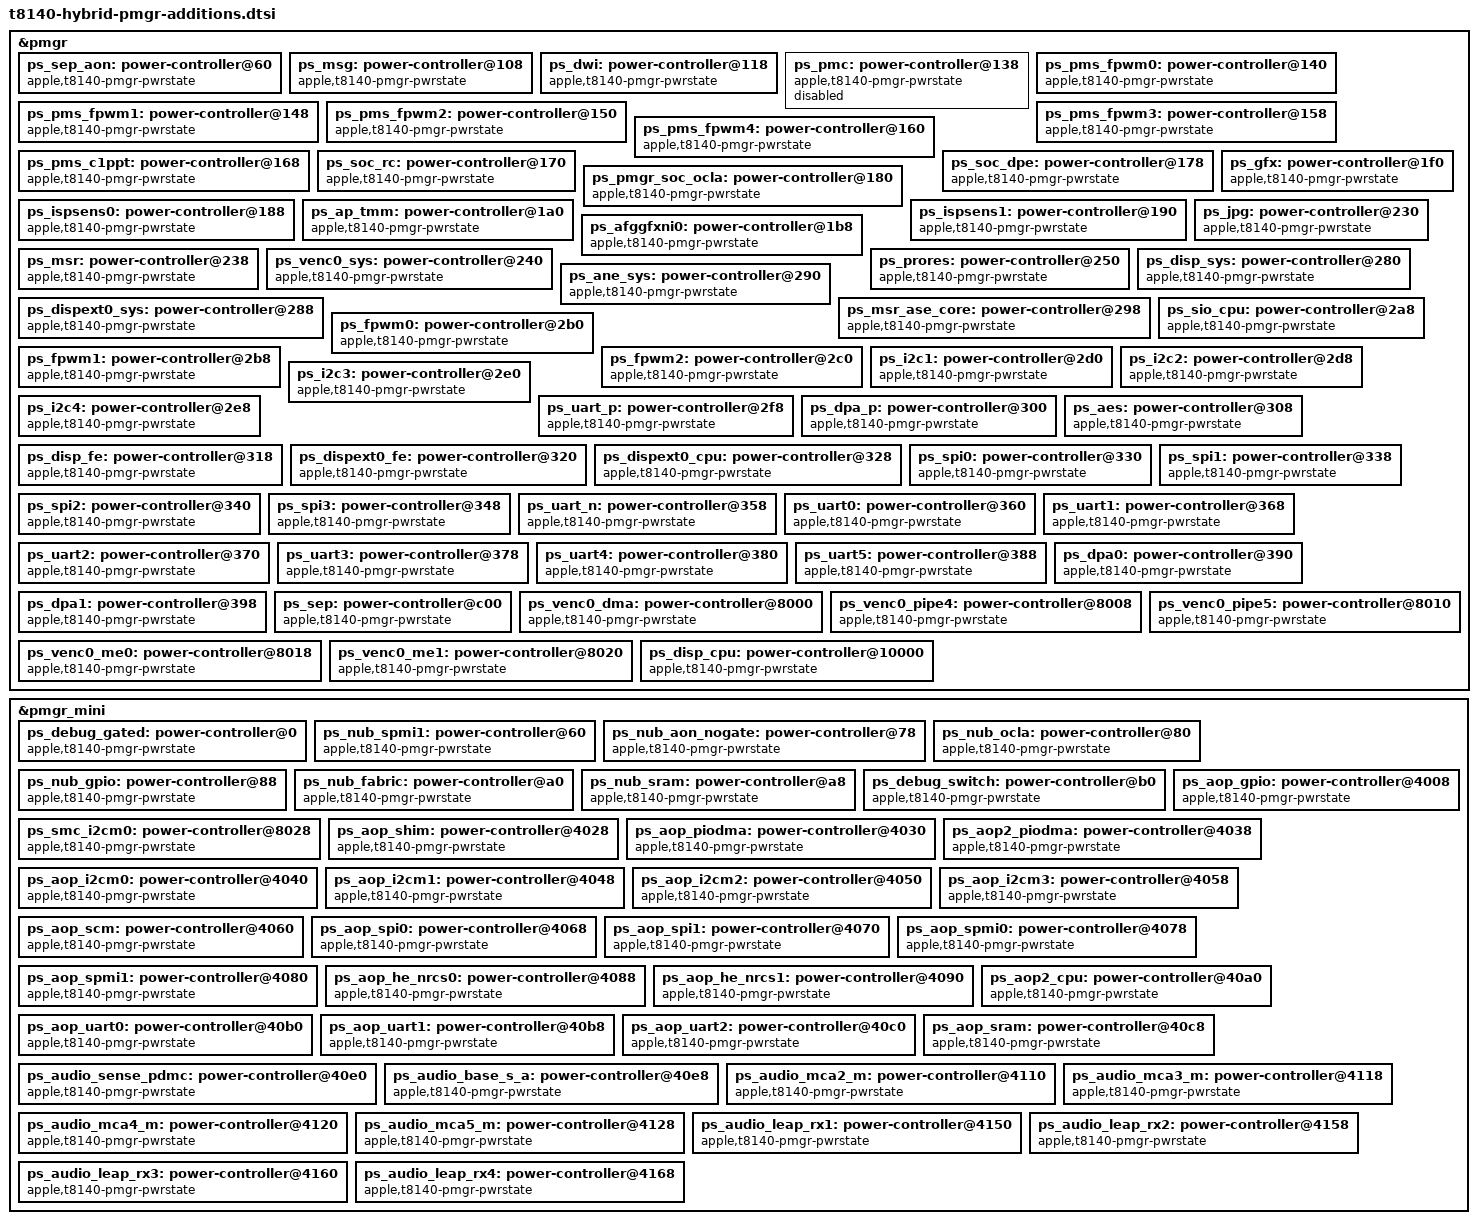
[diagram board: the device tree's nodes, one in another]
// SPDX-License-Identifier: GPL-2.0+ OR MIT
/* Accepted full-platform companion nodes from Linux 2954e3f8; clean t8140-pmgr.dtsi remains authoritative for shared CPU, ANS, PMP and AV nodes. */

&pmgr {
	ps_sep_aon: power-controller@60 {
			compatible = "apple,t8140-pmgr-pwrstate", "apple,t8103-pmgr-pwrstate";
			reg = <0x60 4>;
			#power-domain-cells = <0>;
			#reset-cells = <0>;
			label = "sep_aon";
			apple,always-on;
		};
};

&pmgr {
	ps_msg: power-controller@108 {
			compatible = "apple,t8140-pmgr-pwrstate", "apple,t8103-pmgr-pwrstate";
			reg = <0x108 4>;
			#power-domain-cells = <0>;
			#reset-cells = <0>;
			label = "msg";
		};
};

&pmgr {
	ps_dwi: power-controller@118 {
			compatible = "apple,t8140-pmgr-pwrstate", "apple,t8103-pmgr-pwrstate";
			reg = <0x118 4>;
			#power-domain-cells = <0>;
			#reset-cells = <0>;
			label = "dwi";
		};
};

&pmgr {
	ps_pmc: power-controller@138 {
			compatible = "apple,t8140-pmgr-pwrstate", "apple,t8103-pmgr-pwrstate";
			reg = <0x138 4>;
			#power-domain-cells = <0>;
			#reset-cells = <0>;
			label = "pmc";
			/* Preserve iBoot's PMC state while the PMP firmware boots. */
			status = "disabled";
		};
};

&pmgr {
	ps_pms_fpwm0: power-controller@140 {
			compatible = "apple,t8140-pmgr-pwrstate", "apple,t8103-pmgr-pwrstate";
			reg = <0x140 4>;
			#power-domain-cells = <0>;
			#reset-cells = <0>;
			label = "pms_fpwm0";
		};
};

&pmgr {
	ps_pms_fpwm1: power-controller@148 {
			compatible = "apple,t8140-pmgr-pwrstate", "apple,t8103-pmgr-pwrstate";
			reg = <0x148 4>;
			#power-domain-cells = <0>;
			#reset-cells = <0>;
			label = "pms_fpwm1";
		};
};

&pmgr {
	ps_pms_fpwm2: power-controller@150 {
			compatible = "apple,t8140-pmgr-pwrstate", "apple,t8103-pmgr-pwrstate";
			reg = <0x150 4>;
			#power-domain-cells = <0>;
			#reset-cells = <0>;
			label = "pms_fpwm2";
		};
};

&pmgr {
	ps_pms_fpwm3: power-controller@158 {
			compatible = "apple,t8140-pmgr-pwrstate", "apple,t8103-pmgr-pwrstate";
			reg = <0x158 4>;
			#power-domain-cells = <0>;
			#reset-cells = <0>;
			label = "pms_fpwm3";
		};
};

&pmgr {
	ps_pms_fpwm4: power-controller@160 {
			compatible = "apple,t8140-pmgr-pwrstate", "apple,t8103-pmgr-pwrstate";
			reg = <0x160 4>;
			#power-domain-cells = <0>;
			#reset-cells = <0>;
			label = "pms_fpwm4";
		};
};

&pmgr {
	ps_pms_c1ppt: power-controller@168 {
			compatible = "apple,t8140-pmgr-pwrstate", "apple,t8103-pmgr-pwrstate";
			reg = <0x168 4>;
			#power-domain-cells = <0>;
			#reset-cells = <0>;
			label = "pms_c1ppt";
			apple,always-on;
		};
};

&pmgr {
	ps_soc_rc: power-controller@170 {
			compatible = "apple,t8140-pmgr-pwrstate", "apple,t8103-pmgr-pwrstate";
			reg = <0x170 4>;
			#power-domain-cells = <0>;
			#reset-cells = <0>;
			label = "soc_rc";
		};
};

&pmgr {
	ps_soc_dpe: power-controller@178 {
			compatible = "apple,t8140-pmgr-pwrstate", "apple,t8103-pmgr-pwrstate";
			reg = <0x178 4>;
			#power-domain-cells = <0>;
			#reset-cells = <0>;
			label = "soc_dpe";
			apple,always-on;
		};
};

&pmgr {
	ps_pmgr_soc_ocla: power-controller@180 {
			compatible = "apple,t8140-pmgr-pwrstate", "apple,t8103-pmgr-pwrstate";
			reg = <0x180 4>;
			#power-domain-cells = <0>;
			#reset-cells = <0>;
			label = "pmgr_soc_ocla";
		};
};

&pmgr {
	ps_ispsens0: power-controller@188 {
			compatible = "apple,t8140-pmgr-pwrstate", "apple,t8103-pmgr-pwrstate";
			reg = <0x188 4>;
			#power-domain-cells = <0>;
			#reset-cells = <0>;
			label = "ispsens0";
		};
};

&pmgr {
	ps_ispsens1: power-controller@190 {
			compatible = "apple,t8140-pmgr-pwrstate", "apple,t8103-pmgr-pwrstate";
			reg = <0x190 4>;
			#power-domain-cells = <0>;
			#reset-cells = <0>;
			label = "ispsens1";
		};
};

&pmgr {
	ps_ap_tmm: power-controller@1a0 {
			compatible = "apple,t8140-pmgr-pwrstate", "apple,t8103-pmgr-pwrstate";
			reg = <0x1a0 4>;
			#power-domain-cells = <0>;
			#reset-cells = <0>;
			label = "ap_tmm";
		};
};

&pmgr {
	ps_afggfxni0: power-controller@1b8 {
			compatible = "apple,t8140-pmgr-pwrstate", "apple,t8103-pmgr-pwrstate";
			reg = <0x1b8 4>;
			#power-domain-cells = <0>;
			#reset-cells = <0>;
			label = "afggfxni0";
			apple,always-on;
		};
};

&pmgr {
	ps_gfx: power-controller@1f0 {
			compatible = "apple,t8140-pmgr-pwrstate", "apple,t8103-pmgr-pwrstate";
			reg = <0x1f0 4>;
			#power-domain-cells = <0>;
			#reset-cells = <0>;
			label = "gfx";
		};
};

&pmgr {
	ps_jpg: power-controller@230 {
			compatible = "apple,t8140-pmgr-pwrstate", "apple,t8103-pmgr-pwrstate";
			reg = <0x230 4>;
			#power-domain-cells = <0>;
			#reset-cells = <0>;
			label = "jpg";
		};
};

&pmgr {
	ps_msr: power-controller@238 {
			compatible = "apple,t8140-pmgr-pwrstate", "apple,t8103-pmgr-pwrstate";
			reg = <0x238 4>;
			#power-domain-cells = <0>;
			#reset-cells = <0>;
			label = "msr";
		};
};

&pmgr {
	ps_venc0_sys: power-controller@240 {
			compatible = "apple,t8140-pmgr-pwrstate", "apple,t8103-pmgr-pwrstate";
			reg = <0x240 4>;
			#power-domain-cells = <0>;
			#reset-cells = <0>;
			label = "venc0_sys";
		};
};

&pmgr {
	ps_prores: power-controller@250 {
			compatible = "apple,t8140-pmgr-pwrstate", "apple,t8103-pmgr-pwrstate";
			reg = <0x250 4>;
			#power-domain-cells = <0>;
			#reset-cells = <0>;
			label = "prores";
		};
};

&pmgr {
	ps_disp_sys: power-controller@280 {
			compatible = "apple,t8140-pmgr-pwrstate", "apple,t8103-pmgr-pwrstate";
			reg = <0x280 4>;
			#power-domain-cells = <0>;
			#reset-cells = <0>;
			label = "disp_sys";
			apple,always-on; /* TODO: figure out if we can enable PM here */
		};
};

&pmgr {
	ps_dispext0_sys: power-controller@288 {
			compatible = "apple,t8140-pmgr-pwrstate", "apple,t8103-pmgr-pwrstate";
			reg = <0x288 4>;
			#power-domain-cells = <0>;
			#reset-cells = <0>;
			label = "dispext0_sys";
		};
};

&pmgr {
	ps_ane_sys: power-controller@290 {
			compatible = "apple,t8140-pmgr-pwrstate", "apple,t8103-pmgr-pwrstate";
			reg = <0x290 4>;
			#power-domain-cells = <0>;
			#reset-cells = <0>;
			label = "ane_sys";
		};
};

&pmgr {
	ps_msr_ase_core: power-controller@298 {
			compatible = "apple,t8140-pmgr-pwrstate", "apple,t8103-pmgr-pwrstate";
			reg = <0x298 4>;
			#power-domain-cells = <0>;
			#reset-cells = <0>;
			label = "msr_ase_core";
			power-domains = <&ps_msr>;
		};
};

&pmgr {
	ps_sio_cpu: power-controller@2a8 {
			compatible = "apple,t8140-pmgr-pwrstate", "apple,t8103-pmgr-pwrstate";
			reg = <0x2a8 4>;
			#power-domain-cells = <0>;
			#reset-cells = <0>;
			label = "sio_cpu";
		};
};

&pmgr {
	ps_fpwm0: power-controller@2b0 {
			compatible = "apple,t8140-pmgr-pwrstate", "apple,t8103-pmgr-pwrstate";
			reg = <0x2b0 4>;
			#power-domain-cells = <0>;
			#reset-cells = <0>;
			label = "fpwm0";
		};
};

&pmgr {
	ps_fpwm1: power-controller@2b8 {
			compatible = "apple,t8140-pmgr-pwrstate", "apple,t8103-pmgr-pwrstate";
			reg = <0x2b8 4>;
			#power-domain-cells = <0>;
			#reset-cells = <0>;
			label = "fpwm1";
		};
};

&pmgr {
	ps_fpwm2: power-controller@2c0 {
			compatible = "apple,t8140-pmgr-pwrstate", "apple,t8103-pmgr-pwrstate";
			reg = <0x2c0 4>;
			#power-domain-cells = <0>;
			#reset-cells = <0>;
			label = "fpwm2";
		};
};

&pmgr {
	ps_i2c1: power-controller@2d0 {
			compatible = "apple,t8140-pmgr-pwrstate", "apple,t8103-pmgr-pwrstate";
			reg = <0x2d0 4>;
			#power-domain-cells = <0>;
			#reset-cells = <0>;
			label = "i2c1";
		};
};

&pmgr {
	ps_i2c2: power-controller@2d8 {
			compatible = "apple,t8140-pmgr-pwrstate", "apple,t8103-pmgr-pwrstate";
			reg = <0x2d8 4>;
			#power-domain-cells = <0>;
			#reset-cells = <0>;
			label = "i2c2";
		};
};

&pmgr {
	ps_i2c3: power-controller@2e0 {
			compatible = "apple,t8140-pmgr-pwrstate", "apple,t8103-pmgr-pwrstate";
			reg = <0x2e0 4>;
			#power-domain-cells = <0>;
			#reset-cells = <0>;
			label = "i2c3";
		};
};

&pmgr {
	ps_i2c4: power-controller@2e8 {
			compatible = "apple,t8140-pmgr-pwrstate", "apple,t8103-pmgr-pwrstate";
			reg = <0x2e8 4>;
			#power-domain-cells = <0>;
			#reset-cells = <0>;
			label = "i2c4";
		};
};

&pmgr {
	ps_uart_p: power-controller@2f8 {
			compatible = "apple,t8140-pmgr-pwrstate", "apple,t8103-pmgr-pwrstate";
			reg = <0x2f8 4>;
			#power-domain-cells = <0>;
			#reset-cells = <0>;
			label = "uart_p";
		};
};

&pmgr {
	ps_dpa_p: power-controller@300 {
			compatible = "apple,t8140-pmgr-pwrstate", "apple,t8103-pmgr-pwrstate";
			reg = <0x300 4>;
			#power-domain-cells = <0>;
			#reset-cells = <0>;
			label = "dpa_p";
			apple,always-on;
		};
};

&pmgr {
	ps_aes: power-controller@308 {
			compatible = "apple,t8140-pmgr-pwrstate", "apple,t8103-pmgr-pwrstate";
			reg = <0x308 4>;
			#power-domain-cells = <0>;
			#reset-cells = <0>;
			label = "aes";
		};
};

&pmgr {
	ps_disp_fe: power-controller@318 {
			compatible = "apple,t8140-pmgr-pwrstate", "apple,t8103-pmgr-pwrstate";
			reg = <0x318 4>;
			#power-domain-cells = <0>;
			#reset-cells = <0>;
			label = "disp_fe";
			power-domains = <&ps_disp_sys>;
			apple,always-on; /* TODO: figure out if we can enable PM here */
		};
};

&pmgr {
	ps_dispext0_fe: power-controller@320 {
			compatible = "apple,t8140-pmgr-pwrstate", "apple,t8103-pmgr-pwrstate";
			reg = <0x320 4>;
			#power-domain-cells = <0>;
			#reset-cells = <0>;
			label = "dispext0_fe";
			power-domains = <&ps_dispext0_sys>;
		};
};

&pmgr {
	ps_dispext0_cpu: power-controller@328 {
			compatible = "apple,t8140-pmgr-pwrstate", "apple,t8103-pmgr-pwrstate";
			reg = <0x328 4>;
			#power-domain-cells = <0>;
			#reset-cells = <0>;
			label = "dispext0_cpu";
			power-domains = <&ps_dispext0_fe>;
		};
};

&pmgr {
	ps_spi0: power-controller@330 {
			compatible = "apple,t8140-pmgr-pwrstate", "apple,t8103-pmgr-pwrstate";
			reg = <0x330 4>;
			#power-domain-cells = <0>;
			#reset-cells = <0>;
			label = "spi0";
			power-domains = <&ps_spi_p>;
		};
};

&pmgr {
	ps_spi1: power-controller@338 {
			compatible = "apple,t8140-pmgr-pwrstate", "apple,t8103-pmgr-pwrstate";
			reg = <0x338 4>;
			#power-domain-cells = <0>;
			#reset-cells = <0>;
			label = "spi1";
			power-domains = <&ps_spi_p>;
		};
};

&pmgr {
	ps_spi2: power-controller@340 {
			compatible = "apple,t8140-pmgr-pwrstate", "apple,t8103-pmgr-pwrstate";
			reg = <0x340 4>;
			#power-domain-cells = <0>;
			#reset-cells = <0>;
			label = "spi2";
			power-domains = <&ps_spi_p>;
		};
};

&pmgr {
	ps_spi3: power-controller@348 {
			compatible = "apple,t8140-pmgr-pwrstate", "apple,t8103-pmgr-pwrstate";
			reg = <0x348 4>;
			#power-domain-cells = <0>;
			#reset-cells = <0>;
			label = "spi3";
			power-domains = <&ps_spi_p>;
		};
};

&pmgr {
	ps_uart_n: power-controller@358 {
			compatible = "apple,t8140-pmgr-pwrstate", "apple,t8103-pmgr-pwrstate";
			reg = <0x358 4>;
			#power-domain-cells = <0>;
			#reset-cells = <0>;
			label = "uart_n";
			power-domains = <&ps_uart_p>;
		};
};

&pmgr {
	ps_uart0: power-controller@360 {
			compatible = "apple,t8140-pmgr-pwrstate", "apple,t8103-pmgr-pwrstate";
			reg = <0x360 4>;
			#power-domain-cells = <0>;
			#reset-cells = <0>;
			label = "uart0";
			power-domains = <&ps_uart_p>;
		};
};

&pmgr {
	ps_uart1: power-controller@368 {
			compatible = "apple,t8140-pmgr-pwrstate", "apple,t8103-pmgr-pwrstate";
			reg = <0x368 4>;
			#power-domain-cells = <0>;
			#reset-cells = <0>;
			label = "uart1";
			power-domains = <&ps_uart_p>;
		};
};

&pmgr {
	ps_uart2: power-controller@370 {
			compatible = "apple,t8140-pmgr-pwrstate", "apple,t8103-pmgr-pwrstate";
			reg = <0x370 4>;
			#power-domain-cells = <0>;
			#reset-cells = <0>;
			label = "uart2";
			power-domains = <&ps_uart_p>;
		};
};

&pmgr {
	ps_uart3: power-controller@378 {
			compatible = "apple,t8140-pmgr-pwrstate", "apple,t8103-pmgr-pwrstate";
			reg = <0x378 4>;
			#power-domain-cells = <0>;
			#reset-cells = <0>;
			label = "uart3";
			power-domains = <&ps_uart_p>;
		};
};

&pmgr {
	ps_uart4: power-controller@380 {
			compatible = "apple,t8140-pmgr-pwrstate", "apple,t8103-pmgr-pwrstate";
			reg = <0x380 4>;
			#power-domain-cells = <0>;
			#reset-cells = <0>;
			label = "uart4";
			power-domains = <&ps_uart_p>;
		};
};

&pmgr {
	ps_uart5: power-controller@388 {
			compatible = "apple,t8140-pmgr-pwrstate", "apple,t8103-pmgr-pwrstate";
			reg = <0x388 4>;
			#power-domain-cells = <0>;
			#reset-cells = <0>;
			label = "uart5";
			power-domains = <&ps_uart_p>;
		};
};

&pmgr {
	ps_dpa0: power-controller@390 {
			compatible = "apple,t8140-pmgr-pwrstate", "apple,t8103-pmgr-pwrstate";
			reg = <0x390 4>;
			#power-domain-cells = <0>;
			#reset-cells = <0>;
			label = "dpa0";
			power-domains = <&ps_dpa_p>;
		};
};

&pmgr {
	ps_dpa1: power-controller@398 {
			compatible = "apple,t8140-pmgr-pwrstate", "apple,t8103-pmgr-pwrstate";
			reg = <0x398 4>;
			#power-domain-cells = <0>;
			#reset-cells = <0>;
			label = "dpa1";
			power-domains = <&ps_dpa_p>;
		};
};

&pmgr {
};

&pmgr {
};

&pmgr {
};

&pmgr {
	ps_sep: power-controller@c00 {
			compatible = "apple,t8140-pmgr-pwrstate", "apple,t8103-pmgr-pwrstate";
			reg = <0xc00 4>;
			#power-domain-cells = <0>;
			#reset-cells = <0>;
			label = "sep";
			apple,always-on;
		};
};

&pmgr {
	ps_venc0_dma: power-controller@8000 {
			compatible = "apple,t8140-pmgr-pwrstate", "apple,t8103-pmgr-pwrstate";
			reg = <0x8000 4>;
			#power-domain-cells = <0>;
			#reset-cells = <0>;
			label = "venc0_dma";
			power-domains = <&ps_venc0_sys>;
		};
};

&pmgr {
	ps_venc0_pipe4: power-controller@8008 {
			compatible = "apple,t8140-pmgr-pwrstate", "apple,t8103-pmgr-pwrstate";
			reg = <0x8008 4>;
			#power-domain-cells = <0>;
			#reset-cells = <0>;
			label = "venc0_pipe4";
			power-domains = <&ps_venc0_dma>;
		};
};

&pmgr {
	ps_venc0_pipe5: power-controller@8010 {
			compatible = "apple,t8140-pmgr-pwrstate", "apple,t8103-pmgr-pwrstate";
			reg = <0x8010 4>;
			#power-domain-cells = <0>;
			#reset-cells = <0>;
			label = "venc0_pipe5";
			power-domains = <&ps_venc0_dma>;
		};
};

&pmgr {
	ps_venc0_me0: power-controller@8018 {
			compatible = "apple,t8140-pmgr-pwrstate", "apple,t8103-pmgr-pwrstate";
			reg = <0x8018 4>;
			#power-domain-cells = <0>;
			#reset-cells = <0>;
			label = "venc0_me0";
			power-domains = <&ps_venc0_dma>;
		};
};

&pmgr {
	ps_venc0_me1: power-controller@8020 {
			compatible = "apple,t8140-pmgr-pwrstate", "apple,t8103-pmgr-pwrstate";
			reg = <0x8020 4>;
			#power-domain-cells = <0>;
			#reset-cells = <0>;
			label = "venc0_me1";
			power-domains = <&ps_venc0_me0>;
		};
};

&pmgr {
	ps_disp_cpu: power-controller@10000 {
			compatible = "apple,t8140-pmgr-pwrstate", "apple,t8103-pmgr-pwrstate";
			reg = <0x10000 4>;
			#power-domain-cells = <0>;
			#reset-cells = <0>;
			label = "disp_cpu";
			power-domains = <&ps_disp_fe>;
		};
};

&pmgr_mini {
	ps_debug_gated: power-controller@0 {
			compatible = "apple,t8140-pmgr-pwrstate", "apple,t8103-pmgr-pwrstate";
			reg = <0x0 4>;
			#power-domain-cells = <0>;
			#reset-cells = <0>;
			label = "debug_gated";
			apple,always-on;
		};
};

&pmgr_mini {
	ps_nub_spmi1: power-controller@60 {
			compatible = "apple,t8140-pmgr-pwrstate", "apple,t8103-pmgr-pwrstate";
			reg = <0x60 4>;
			#power-domain-cells = <0>;
			#reset-cells = <0>;
			label = "nub_spmi1";
			apple,always-on;
		};
};

&pmgr_mini {
};

&pmgr_mini {
	ps_nub_aon_nogate: power-controller@78 {
			compatible = "apple,t8140-pmgr-pwrstate", "apple,t8103-pmgr-pwrstate";
			reg = <0x78 4>;
			#power-domain-cells = <0>;
			#reset-cells = <0>;
			label = "nub_aon_nogate";
			apple,always-on;
		};
};

&pmgr_mini {
	ps_nub_ocla: power-controller@80 {
			compatible = "apple,t8140-pmgr-pwrstate", "apple,t8103-pmgr-pwrstate";
			reg = <0x80 4>;
			#power-domain-cells = <0>;
			#reset-cells = <0>;
			label = "nub_ocla";
			apple,always-on;
		};
};

&pmgr_mini {
	ps_nub_gpio: power-controller@88 {
			compatible = "apple,t8140-pmgr-pwrstate", "apple,t8103-pmgr-pwrstate";
			reg = <0x88 4>;
			#power-domain-cells = <0>;
			#reset-cells = <0>;
			label = "nub_gpio";
			apple,always-on;
		};
};

&pmgr_mini {
	ps_nub_fabric: power-controller@a0 {
			compatible = "apple,t8140-pmgr-pwrstate", "apple,t8103-pmgr-pwrstate";
			reg = <0xa0 4>;
			#power-domain-cells = <0>;
			#reset-cells = <0>;
			label = "nub_fabric";
			apple,always-on;
		};
};

&pmgr_mini {
	ps_nub_sram: power-controller@a8 {
			compatible = "apple,t8140-pmgr-pwrstate", "apple,t8103-pmgr-pwrstate";
			reg = <0xa8 4>;
			#power-domain-cells = <0>;
			#reset-cells = <0>;
			label = "nub_sram";
			apple,always-on;
		};
};

&pmgr_mini {
	ps_debug_switch: power-controller@b0 {
			compatible = "apple,t8140-pmgr-pwrstate", "apple,t8103-pmgr-pwrstate";
			reg = <0xb0 4>;
			#power-domain-cells = <0>;
			#reset-cells = <0>;
			label = "debug_switch";
			apple,always-on;
		};
};

&pmgr_mini {
	ps_smc_i2cm0: power-controller@8028 {
			compatible = "apple,t8140-pmgr-pwrstate", "apple,t8103-pmgr-pwrstate";
			reg = <0x8028 4>;
			#power-domain-cells = <0>;
			#reset-cells = <0>;
			label = "smc_i2cm0";
		};
};

&pmgr_mini {
	ps_aop_gpio: power-controller@4008 {
			compatible = "apple,t8140-pmgr-pwrstate", "apple,t8103-pmgr-pwrstate";
			reg = <0x4008 4>;
			#power-domain-cells = <0>;
			#reset-cells = <0>;
			label = "aop_gpio";
			power-domains = <&ps_aop_filter>;
			apple,always-on;
		};
};

&pmgr_mini {
	ps_aop_shim: power-controller@4028 {
			compatible = "apple,t8140-pmgr-pwrstate", "apple,t8103-pmgr-pwrstate";
			reg = <0x4028 4>;
			#power-domain-cells = <0>;
			#reset-cells = <0>;
			label = "aop_shim";
			power-domains = <&ps_aop_base>;
			apple,always-on;
		};
};

&pmgr_mini {
	ps_aop_piodma: power-controller@4030 {
			compatible = "apple,t8140-pmgr-pwrstate", "apple,t8103-pmgr-pwrstate";
			reg = <0x4030 4>;
			#power-domain-cells = <0>;
			#reset-cells = <0>;
			label = "aop_piodma";
			power-domains = <&ps_aop_base>;
			apple,always-on;
		};
};

&pmgr_mini {
	ps_aop2_piodma: power-controller@4038 {
			compatible = "apple,t8140-pmgr-pwrstate", "apple,t8103-pmgr-pwrstate";
			reg = <0x4038 4>;
			#power-domain-cells = <0>;
			#reset-cells = <0>;
			label = "aop2_piodma";
			power-domains = <&ps_aop_base>;
		};
};

&pmgr_mini {
	ps_aop_i2cm0: power-controller@4040 {
			compatible = "apple,t8140-pmgr-pwrstate", "apple,t8103-pmgr-pwrstate";
			reg = <0x4040 4>;
			#power-domain-cells = <0>;
			#reset-cells = <0>;
			label = "aop_i2cm0";
			power-domains = <&ps_aop_fr>;
			apple,always-on;
		};
};

&pmgr_mini {
	ps_aop_i2cm1: power-controller@4048 {
			compatible = "apple,t8140-pmgr-pwrstate", "apple,t8103-pmgr-pwrstate";
			reg = <0x4048 4>;
			#power-domain-cells = <0>;
			#reset-cells = <0>;
			label = "aop_i2cm1";
			power-domains = <&ps_aop_fr>;
			apple,always-on;
		};
};

&pmgr_mini {
	ps_aop_i2cm2: power-controller@4050 {
			compatible = "apple,t8140-pmgr-pwrstate", "apple,t8103-pmgr-pwrstate";
			reg = <0x4050 4>;
			#power-domain-cells = <0>;
			#reset-cells = <0>;
			label = "aop_i2cm2";
			power-domains = <&ps_aop_fr>;
			apple,always-on;
		};
};

&pmgr_mini {
	ps_aop_i2cm3: power-controller@4058 {
			compatible = "apple,t8140-pmgr-pwrstate", "apple,t8103-pmgr-pwrstate";
			reg = <0x4058 4>;
			#power-domain-cells = <0>;
			#reset-cells = <0>;
			label = "aop_i2cm3";
			power-domains = <&ps_aop_fr>;
		};
};

&pmgr_mini {
	ps_aop_scm: power-controller@4060 {
			compatible = "apple,t8140-pmgr-pwrstate", "apple,t8103-pmgr-pwrstate";
			reg = <0x4060 4>;
			#power-domain-cells = <0>;
			#reset-cells = <0>;
			label = "aop_scm";
			power-domains = <&ps_aop_base>, <&ps_aop_fr>;
			apple,always-on;
		};
};

&pmgr_mini {
	ps_aop_spi0: power-controller@4068 {
			compatible = "apple,t8140-pmgr-pwrstate", "apple,t8103-pmgr-pwrstate";
			reg = <0x4068 4>;
			#power-domain-cells = <0>;
			#reset-cells = <0>;
			label = "aop_spi0";
			power-domains = <&ps_aop_fr>;
			apple,always-on;
		};
};

&pmgr_mini {
	ps_aop_spi1: power-controller@4070 {
			compatible = "apple,t8140-pmgr-pwrstate", "apple,t8103-pmgr-pwrstate";
			reg = <0x4070 4>;
			#power-domain-cells = <0>;
			#reset-cells = <0>;
			label = "aop_spi1";
			power-domains = <&ps_aop_fr>;
		};
};

&pmgr_mini {
	ps_aop_spmi0: power-controller@4078 {
			compatible = "apple,t8140-pmgr-pwrstate", "apple,t8103-pmgr-pwrstate";
			reg = <0x4078 4>;
			#power-domain-cells = <0>;
			#reset-cells = <0>;
			label = "aop_spmi0";
			power-domains = <&ps_aop_filter>, <&ps_aop_fr>;
			apple,always-on;
		};
};

&pmgr_mini {
	ps_aop_spmi1: power-controller@4080 {
			compatible = "apple,t8140-pmgr-pwrstate", "apple,t8103-pmgr-pwrstate";
			reg = <0x4080 4>;
			#power-domain-cells = <0>;
			#reset-cells = <0>;
			label = "aop_spmi1";
			power-domains = <&ps_aop_filter>, <&ps_aop_fr>;
			apple,always-on;
		};
};

&pmgr_mini {
	ps_aop_he_nrcs0: power-controller@4088 {
			compatible = "apple,t8140-pmgr-pwrstate", "apple,t8103-pmgr-pwrstate";
			reg = <0x4088 4>;
			#power-domain-cells = <0>;
			#reset-cells = <0>;
			label = "aop_he_nrcs0";
			power-domains = <&ps_aop_fr>;
		};
};

&pmgr_mini {
	ps_aop_he_nrcs1: power-controller@4090 {
			compatible = "apple,t8140-pmgr-pwrstate", "apple,t8103-pmgr-pwrstate";
			reg = <0x4090 4>;
			#power-domain-cells = <0>;
			#reset-cells = <0>;
			label = "aop_he_nrcs1";
			power-domains = <&ps_aop_fr>;
		};
};

&pmgr_mini {
	ps_aop2_cpu: power-controller@40a0 {
			compatible = "apple,t8140-pmgr-pwrstate", "apple,t8103-pmgr-pwrstate";
			reg = <0x40a0 4>;
			#power-domain-cells = <0>;
			#reset-cells = <0>;
			label = "aop2_cpu";
			power-domains = <&ps_aop_base>, <&ps_aop_fr>;
		};
};

&pmgr_mini {
	ps_aop_uart0: power-controller@40b0 {
			compatible = "apple,t8140-pmgr-pwrstate", "apple,t8103-pmgr-pwrstate";
			reg = <0x40b0 4>;
			#power-domain-cells = <0>;
			#reset-cells = <0>;
			label = "aop_uart0";
			power-domains = <&ps_aop_shim>;
			apple,always-on;
		};
};

&pmgr_mini {
	ps_aop_uart1: power-controller@40b8 {
			compatible = "apple,t8140-pmgr-pwrstate", "apple,t8103-pmgr-pwrstate";
			reg = <0x40b8 4>;
			#power-domain-cells = <0>;
			#reset-cells = <0>;
			label = "aop_uart1";
			power-domains = <&ps_aop_shim>;
			apple,always-on;
		};
};

&pmgr_mini {
	ps_aop_uart2: power-controller@40c0 {
			compatible = "apple,t8140-pmgr-pwrstate", "apple,t8103-pmgr-pwrstate";
			reg = <0x40c0 4>;
			#power-domain-cells = <0>;
			#reset-cells = <0>;
			label = "aop_uart2";
			power-domains = <&ps_aop_shim>;
			apple,always-on;
		};
};

&pmgr_mini {
	ps_aop_sram: power-controller@40c8 {
			compatible = "apple,t8140-pmgr-pwrstate", "apple,t8103-pmgr-pwrstate";
			reg = <0x40c8 4>;
			#power-domain-cells = <0>;
			#reset-cells = <0>;
			label = "aop_sram";
			power-domains = <&ps_aop_scm>, <&ps_aop_cpu>;
			apple,always-on;
		};
};

&pmgr_mini {
	ps_audio_sense_pdmc: power-controller@40e0 {
			compatible = "apple,t8140-pmgr-pwrstate", "apple,t8103-pmgr-pwrstate";
			reg = <0x40e0 4>;
			#power-domain-cells = <0>;
			#reset-cells = <0>;
			label = "audio_sense_pdmc";
			power-domains = <&ps_audio_fr>;
		};
};

&pmgr_mini {
	ps_audio_base_s_a: power-controller@40e8 {
			compatible = "apple,t8140-pmgr-pwrstate", "apple,t8103-pmgr-pwrstate";
			reg = <0x40e8 4>;
			#power-domain-cells = <0>;
			#reset-cells = <0>;
			label = "audio_base_s_a";
			power-domains = <&ps_audio_p>;
		};
};

&pmgr_mini {
	ps_audio_mca2_m: power-controller@4110 {
			compatible = "apple,t8140-pmgr-pwrstate", "apple,t8103-pmgr-pwrstate";
			reg = <0x4110 4>;
			#power-domain-cells = <0>;
			#reset-cells = <0>;
			label = "audio_mca2_m";
			power-domains = <&ps_audio_p>;
		};
};

&pmgr_mini {
	ps_audio_mca3_m: power-controller@4118 {
			compatible = "apple,t8140-pmgr-pwrstate", "apple,t8103-pmgr-pwrstate";
			reg = <0x4118 4>;
			#power-domain-cells = <0>;
			#reset-cells = <0>;
			label = "audio_mca3_m";
			power-domains = <&ps_audio_p>;
		};
};

&pmgr_mini {
	ps_audio_mca4_m: power-controller@4120 {
			compatible = "apple,t8140-pmgr-pwrstate", "apple,t8103-pmgr-pwrstate";
			reg = <0x4120 4>;
			#power-domain-cells = <0>;
			#reset-cells = <0>;
			label = "audio_mca4_m";
			power-domains = <&ps_audio_p>;
		};
};

&pmgr_mini {
	ps_audio_mca5_m: power-controller@4128 {
			compatible = "apple,t8140-pmgr-pwrstate", "apple,t8103-pmgr-pwrstate";
			reg = <0x4128 4>;
			#power-domain-cells = <0>;
			#reset-cells = <0>;
			label = "audio_mca5_m";
			power-domains = <&ps_audio_p>;
		};
};

&pmgr_mini {
	ps_audio_leap_rx1: power-controller@4150 {
			compatible = "apple,t8140-pmgr-pwrstate", "apple,t8103-pmgr-pwrstate";
			reg = <0x4150 4>;
			#power-domain-cells = <0>;
			#reset-cells = <0>;
			label = "audio_leap_rx1";
			power-domains = <&ps_audio_leap_c>;
		};
};

&pmgr_mini {
	ps_audio_leap_rx2: power-controller@4158 {
			compatible = "apple,t8140-pmgr-pwrstate", "apple,t8103-pmgr-pwrstate";
			reg = <0x4158 4>;
			#power-domain-cells = <0>;
			#reset-cells = <0>;
			label = "audio_leap_rx2";
			power-domains = <&ps_audio_leap_c>;
		};
};

&pmgr_mini {
	ps_audio_leap_rx3: power-controller@4160 {
			compatible = "apple,t8140-pmgr-pwrstate", "apple,t8103-pmgr-pwrstate";
			reg = <0x4160 4>;
			#power-domain-cells = <0>;
			#reset-cells = <0>;
			label = "audio_leap_rx3";
			power-domains = <&ps_audio_leap_c>;
		};
};

&pmgr_mini {
	ps_audio_leap_rx4: power-controller@4168 {
			compatible = "apple,t8140-pmgr-pwrstate", "apple,t8103-pmgr-pwrstate";
			reg = <0x4168 4>;
			#power-domain-cells = <0>;
			#reset-cells = <0>;
			label = "audio_leap_rx4";
			power-domains = <&ps_audio_leap_c>;
		};
};
